# MDR1206AFI register map
Vendor: Milandr; File version: 2.0
CPU: BM-310S0, little endian
Registers are 32-bit, read-write, reset 0x0 unless marked. A register's access mark holds for its fields unless they carry their own. Offsets are from the block's base; [hi:lo] are bit positions; {n}, {i} and the like mark numbered series; 'fields as' and 'values as' point back to an identical list.

## TIMER1 — General purpose TIMER1
Base 0x50070000
Same registers: TIMER2 0x50078000, TIMER3 0x500D8000, TIMER4 0x500E0000
0x00 CNT — Counter
0x04 PSG — Prescaler value. TIM_CLKd = TIM_CLK/(PSG+1)
0x08 ARR — Auto-reload register
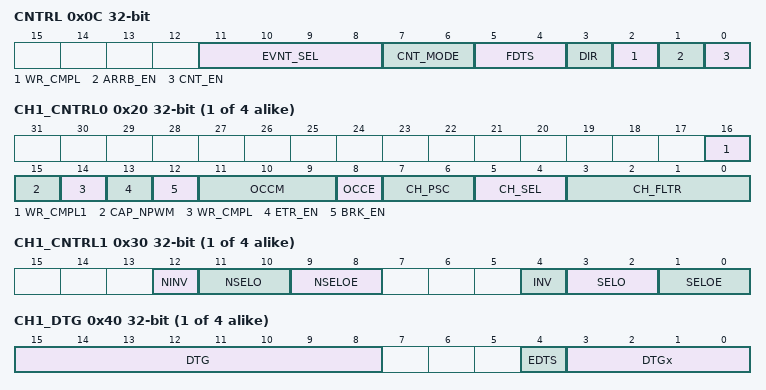
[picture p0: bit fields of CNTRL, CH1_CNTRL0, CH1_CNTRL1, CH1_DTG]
0x0C CNTRL — Control register
  [11:8] EVNT_SEL — Selects a source which triggers events
    0=Int_CLOCK (TIM_CLKd); 1=TIM1 (CNT == ARR in Timer1); 2=TIM2 (CNT == ARR in Timer2); 3=TIM3 (CNT == ARR in Timer3); {v}=CH{v-3} (Rising edge, mode 1) (v=4..7); 8=ETR_POS (Rising edge, mode 2); 9=ETR_NEG (Falling edge, mode 2); 10=TIM4 (CNT == ARR in Timer4)
  [7:6] CNT_MODE — Counter mode
    0=MODE_00 (Direct when DIR=0, backward when DIR=1); 1=MODE_01 (Bidirectional with automatic change of DIR when CNT == 0 or CNT == ARR); 2=MODE_10 (Direct when DIR=0, backward when DIR=1)
  [5:4] FDTS — Clock frequency FDTS
    0=TIM_CLK (FDTS = TIM_CLK); 1=TIM_CLK_2 (FDTS = TIM_CLK/2); 2=TIM_CLK_3 (FDTS = TIM_CLK/3); 3=TIM_CLK_4 (FDTS = TIM_CLK/4)
  [3] DIR — Direction
    0=Direct (From 0 to ARR); 1=Backward (From ARR to 0)
  [2] WR_CMPL ro — Flag denotes if a new value can be written in CNT, PSG, ARR. 1 - writing is in process
  [1] ARRB_EN — Renewal of the ARR
    0=ARR is rewritten when there is a write in ARR; 1=ARR is rewritten when CNT == ARR
  [0] CNT_EN — Enables operation of the timer
{0xC+4i} CH{i}_CCR (i=1..4) — Capture/compare register for channel {i}
{0x1C+4i} CH{i}_CNTRL0 (i=1..4) — CH{i} control register 0
  [16] WR_CMPL1 ro — Flag signals whether a new value can be written in CHy_CCR1
  [15] CAP_NPWM — Channel operating mode
    0=PWM; 1=CAPTURE
  [14] WR_CMPL ro — Flag signals whether a new value can be written in CHy_CCR
  [13] ETR_EN — Enables reset of REF when ETR=0
  [12] BRK_EN — Enables reset of REF and DTG when BRK=0
  [11:9] OCCM — PWM mode. Generation of REF
  [8] OCCE — Enables ETR
  [7:6] CH_PSC — Prescaler for the input channel
    0=NO_DIV; 1=DIV_2 (Division by 2); 2=DIV_4 (Division by 4); 3=DIV_8 (Division by 8)
  [5:4] CH_SEL — Selects an event for CHyi to write the CNT value into CHy_CCR
  [3:0] CH_FLTR — Input filter for the channel
    0=NO_FILTER (FS = FDTS); 1=FILTER_1 (FS = TIM_CLK, N = 2); 2=FILTER_2 (FS = TIM_CLK, N = 4); 3=FILTER_3 (FS = TIM_CLK, N = 8); 4=FILTER_4 (FS = FDTS/2, N = 6); 5=FILTER_5 (FS = FDTS/2, N = 8); 6=FILTER_6 (FS = FDTS/4, N = 6); 7=FILTER_7 (FS = FDTS/4, N = 8); 8=FILTER_8 (FS = FDTS/8, N = 6); 9=FILTER_9 (FS = FDTS/8, N = 8); 10=FILTER_10 (FS = FDTS/16, N = 5); 11=FILTER_11 (FS = FDTS/16, N = 6); 12=FILTER_12 (FS = FDTS/16, N = 8); 13=FILTER_13 (FS = FDTS/32, N = 5); 14=FILTER_14 (FS = FDTS/32, N = 6); 15=FILTER_15 (FS = FDTS/32, N = 8)
{0x2C+4i} CH{i}_CNTRL1 (i=1..4) — CH{i} control register 1
  [12] NINV — Inversion of the inverted output nCHy
  [11:10] NSELO — Selects a source for the inverted output of the channel nCHyo
    0=LOW; 1=HIGH; 2=nREF; 3=DTG
  [9:8] NSELOE — Selects the operating mode of nCHyoe
    0=LOW; 1=HIGH; 2=nREF; 3=DTG
  [4] INV — Inversion of the direct output CHy
  [3:2] SELO — Selects a source for the direct output of the channel CHyo
    0=LOW; 1=HIGH; 2=REF; 3=DTG
  [1:0] SELOE — Selects the operating mode of the direct output of the channel CHyoe
    0=LOW; 1=HIGH; 2=REF; 3=DTG
{0x3C+4i} CH{i}_DTG (i=1..4) — Dead-time register for channel {i}
  [15:8] DTG — Main divisor for DTG. Delay DTGdel = DTG * (DTGx + 1)
  [4] EDTS — DTG clock
    0=TIM_CLK; 1=FDTS
  [3:0] DTGx — DTG clock prescaler
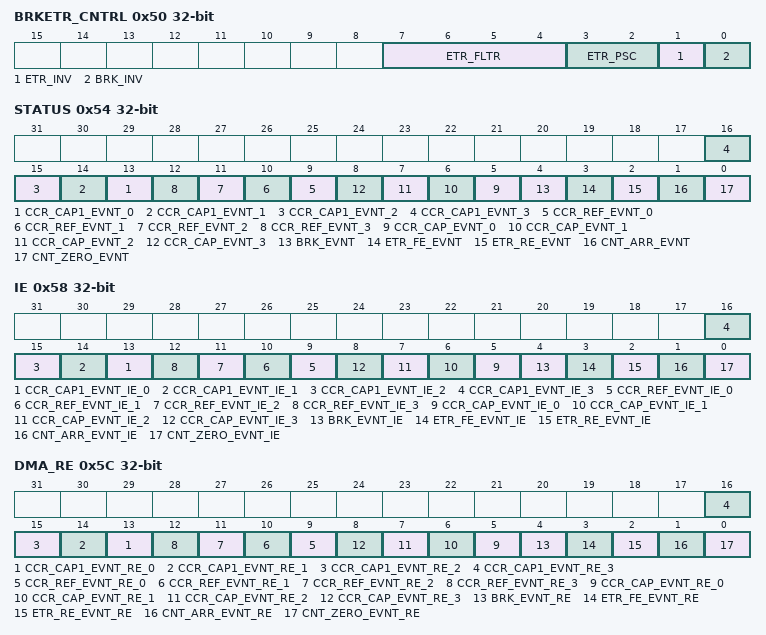
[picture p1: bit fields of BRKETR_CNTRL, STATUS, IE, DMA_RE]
0x50 BRKETR_CNTRL — BRK and ETR control register
  [7:4] ETR_FLTR — ETR digital filter
    values as CH1_CNTRL0.CH_FLTR
  [3:2] ETR_PSC — ETR frequency prescaler
    values as CH1_CNTRL0.CH_PSC
  [1] ETR_INV — ETR inversion
    0=NO_INV; 1=INV
  [0] BRK_INV — BRK inversion
    0=NO_INV; 1=INV
0x54 STATUS — Timer status register
  [n+13] CCR_CAP1_EVNT_{n} (n=0..3) — The counter value CNT is written in the CH{n+1}_CCR1 when there is a selected edge on the CH{n+1}i
  [n+9] CCR_REF_EVNT_{n} (n=0..3) — A rising edge on the output of the reference generator of channel {n+1}
  [n+5] CCR_CAP_EVNT_{n} (n=0..3) — The counter value CNT is written in the CH{n+1}_CCR when there is a selected edge on the CH{n+1}i
  [4] BRK_EVNT — The high level on the BRK. Write as "0" resets the flag if there is low level on the BRK
    0=NO_EVENT; 1=EVENT_HL
  [3] ETR_FE_EVNT — A falling edge on the ETR. Write as "0" resets the flag. A new event has a priority over a "write"
    0=NO_EVENT; 1=EVENT_RE
  [2] ETR_RE_EVNT — A rising edge on the ETR. Write as "0" resets the flag. A new event has a priority over a "write"
    0=NO_EVENT; 1=EVENT_RE
  [1] CNT_ARR_EVNT — CNT coincides with ARR. Write as "0" resets the flag. A new event has a priority over a "write"
    0=NO_EVENT; 1=EVENT_ARR
  [0] CNT_ZERO_EVNT — CNT coincides with zero. Write as "0" resets the flag. A new event has a priority over a "write"
    0=NO_EVENT; 1=EVENT_0
0x58 IE — Interrupt enable register
  [n+13] CCR_CAP1_EVNT_IE_{n} (n=0..3) — Interrupt: The counter value CNT is written in the CH{n+1}_CCR1 when there is a selected edge on the CH{n+1}i
  [n+9] CCR_REF_EVNT_IE_{n} (n=0..3) — Interrupt: A rising edge on the output of the reference generator of channel {n+1}
  [n+5] CCR_CAP_EVNT_IE_{n} (n=0..3) — Interrupt: The counter value CNT is written in the CH{n+1}_CCR when there is a selected edge on the CH{n+1}i
  [4] BRK_EVNT_IE — Interrupt: The high level on the BRK
  [3] ETR_FE_EVNT_IE — Interrupt: A falling edge on the ETR
  [2] ETR_RE_EVNT_IE — Interrupt: A rising edge on the ETR
  [1] CNT_ARR_EVNT_IE — Interrupt: CNT coincides with ARR
  [0] CNT_ZERO_EVNT_IE — Interrupt: CNT coincides with zero
0x5C DMA_RE — The register enables the request for the DMA
  [n+13] CCR_CAP1_EVNT_RE_{n} (n=0..3) — Enables the request when the counter value CNT is written in the CH{n+1}_CCR1 when there is a selected edge on the CH{n+1}i
  [n+9] CCR_REF_EVNT_RE_{n} (n=0..3) — Enables the request when there is a rising edge on the output of the reference generator of channel {n+1}
  [n+5] CCR_CAP_EVNT_RE_{n} (n=0..3) — Enables the request when the counter value CNT is written in the CH{n+1}_CCR when there is a selected edge on the CH{n+1}i
  [4] BRK_EVNT_RE — Enables the request when there is the high level on the BRK
  [3] ETR_FE_EVNT_RE — Enables the request when there is a falling edge on the ETR
  [2] ETR_RE_EVNT_RE — Enables the request when there is a rising edge on the ETR
  [1] CNT_ARR_EVNT_RE — Enables the request when CNT coincides with ARR
  [0] CNT_ZERO_EVNT_RE — Enables the request when CNT coincides with zero
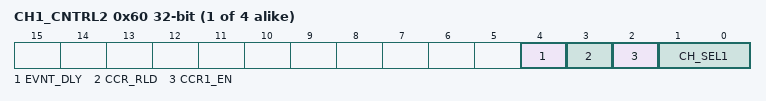
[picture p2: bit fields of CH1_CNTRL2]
{0x5C+4i} CH{i}_CNTRL2 (i=1..4) — Control register 2 for channel {i}
  [4] EVNT_DLY — Delays the capture event until CH_CCR and CH_CCR1 are renewed
    0=NO_DELAY (An immediate signal of the capture event. CH_CCR and CH_CCR1 are renewed in a cycle of TIM_CLK); 1=DELAY (The capture event is set simultaneously with the renewal of CH_CCR and CH_CCR1)
  [3] CCR_RLD — Reloading of the CH_CCR and CH_CCR1
    0=ANY_MOMENT (Renewal is possible at any moment); 1=CNT_0 (Renewal is possible when CNT==0)
  [2] CCR1_EN — Enables CH_CCR
  [1:0] CH_SEL1 — Selects an event on CH1i to fix the CNT value in CH_CCR1
    0=RE_CHi (A rising edge on the CHi); 1=FE_CHi (A falling edge on the CHi); 2=FE_CH_1 (A falling edge from other channels: 1-2, 2-3, 3-4, 4-1); 3=FE_CH_2 (A falling edge from other channels: 1-3, 2-4, 3-1, 4-2)
{0x6C+4i} CH{i}_CCR1 (i=1..4) — Capture/compare register for channel {i}
